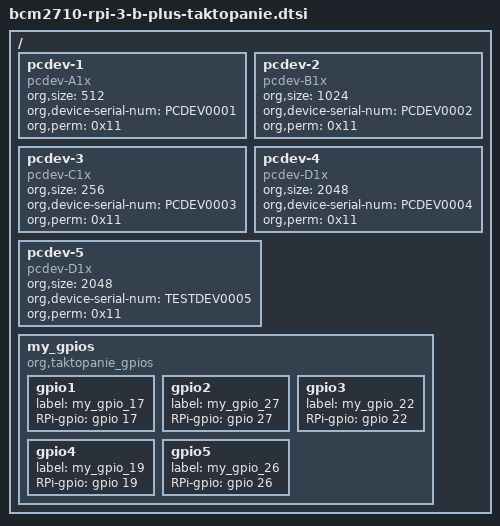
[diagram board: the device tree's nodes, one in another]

/ {
	pcdev-1 {
		compatible = "pcdev-A1x";
		org,size = <512>;
		org,device-serial-num = "PCDEV0001";
		org,perm = <0x11>;
	};

        pcdev-2 {
		compatible = "pcdev-B1x";
                org,size = <1024>;
                org,device-serial-num = "PCDEV0002";
                org,perm = <0x11>;
        };

        pcdev-3 {
		compatible = "pcdev-C1x";	
                org,size = <256>;
                org,device-serial-num = "PCDEV0003";
                org,perm = <0x11>;
        };

        pcdev-4 {
		compatible = "pcdev-D1x","pcdev-A1x";
                org,size = <2048>;
                org,device-serial-num = "PCDEV0004";
                org,perm = <0x11>;
        };

        pcdev-5 {
		compatible = "pcdev-D1x","pcdev-A1x";
                org,size = <2048>;
                org,device-serial-num = "TESTDEV0005";
                org,perm = <0x11>;
        };


        my_gpios{
                compatible = "org,taktopanie_gpios";
                gpio1{
                        label = "my_gpio_17";
                        RPi-gpio = <&gpio 17 GPIO_ACTIVE_HIGH>;
                };
                gpio2{
                        label = "my_gpio_27";
                        RPi-gpio = <&gpio 27 GPIO_ACTIVE_HIGH>;
 
                };
                gpio3{
                        label = "my_gpio_22";
                        RPi-gpio = <&gpio 22 GPIO_ACTIVE_HIGH>;
                };
                gpio4{
                        label = "my_gpio_19";
                        RPi-gpio = <&gpio 19 GPIO_ACTIVE_HIGH>;
                };
                gpio5{
                        label = "my_gpio_26";
                        RPi-gpio = <&gpio 26 GPIO_ACTIVE_HIGH>;
                };
        };



};
